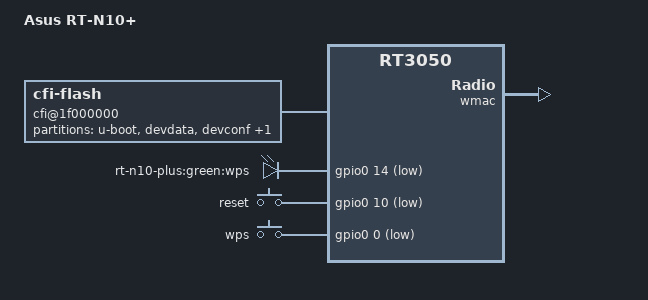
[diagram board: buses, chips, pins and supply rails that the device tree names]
/dts-v1/;

#include "rt3050.dtsi"

#include <dt-bindings/gpio/gpio.h>
#include <dt-bindings/input/input.h>

/ {
	compatible = "asus,rt-n10-plus", "ralink,rt3050-soc";
	model = "Asus RT-N10+";

	aliases {
		led-status = &led_wps;
	};

	cfi@1f000000 {
		compatible = "cfi-flash";
		reg = <0x1f000000 0x800000>;
		bank-width = <2>;
		device-width = <2>;

		partitions {
			compatible = "fixed-partitions";
			#address-cells = <1>;
			#size-cells = <1>;

			partition@0 {
				label = "u-boot";
				reg = <0x0 0x30000>;
				read-only;
			};

			partition@30000 {
				label = "devdata";
				reg = <0x30000 0x10000>;
				read-only;
			};

			devconf: partition@40000 {
				label = "devconf";
				reg = <0x40000 0x10000>;
				read-only;
			};

			partition@50000 {
				label = "firmware";
				reg = <0x50000 0x3b0000>;
			};
		};
	};

	gpio-leds {
		compatible = "gpio-leds";

		led_wps: wps {
			label = "rt-n10-plus:green:wps";
			gpios = <&gpio0 14 GPIO_ACTIVE_LOW>;
		};
	};

	gpio-keys-polled {
		compatible = "gpio-keys-polled";
		poll-interval = <20>;

		reset {
			label = "reset";
			gpios = <&gpio0 10 GPIO_ACTIVE_LOW>;
			linux,code = <KEY_RESTART>;
		};

		wps {
			label = "wps";
			gpios = <&gpio0 0 GPIO_ACTIVE_LOW>;
			linux,code = <KEY_WPS_BUTTON>;
		};
	};
};

&ethernet {
	mtd-mac-address = <&devconf 0x4>;
};

&esw {
	mediatek,portmap = <0x3e>;
};

&wmac {
	ralink,mtd-eeprom = <&devconf 0>;
};
